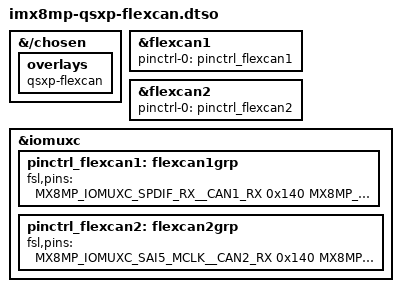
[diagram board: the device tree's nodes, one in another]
// SPDX-License-Identifier: (GPL-2.0 OR MIT)
/*
 * Copyright 2022 Lothar Waßmann <LW@KARO-electronics.de>
 *
 */

/dts-v1/;

/plugin/;

#include "imx8mp-pinfunc.h"

&{/chosen} {
	overlays {
		qsxp-flexcan;
	};
};

&flexcan1 {
	pinctrl-names = "default";
	pinctrl-0 = <&pinctrl_flexcan1>;
	status = "okay";
};

&flexcan2 {
	pinctrl-names = "default";
	pinctrl-0 = <&pinctrl_flexcan2>;
	status = "okay";
};

&iomuxc {
	pinctrl_flexcan1: flexcan1grp {
		fsl,pins = <
			 MX8MP_IOMUXC_SPDIF_RX__CAN1_RX 	0x140
			 MX8MP_IOMUXC_SPDIF_TX__CAN1_TX 	0x140
		>;
	};

	pinctrl_flexcan2: flexcan2grp {
		fsl,pins = <
			 MX8MP_IOMUXC_SAI5_MCLK__CAN2_RX	0x140
			 MX8MP_IOMUXC_SAI5_RXD3__CAN2_TX	0x140
		>;
	};
};
